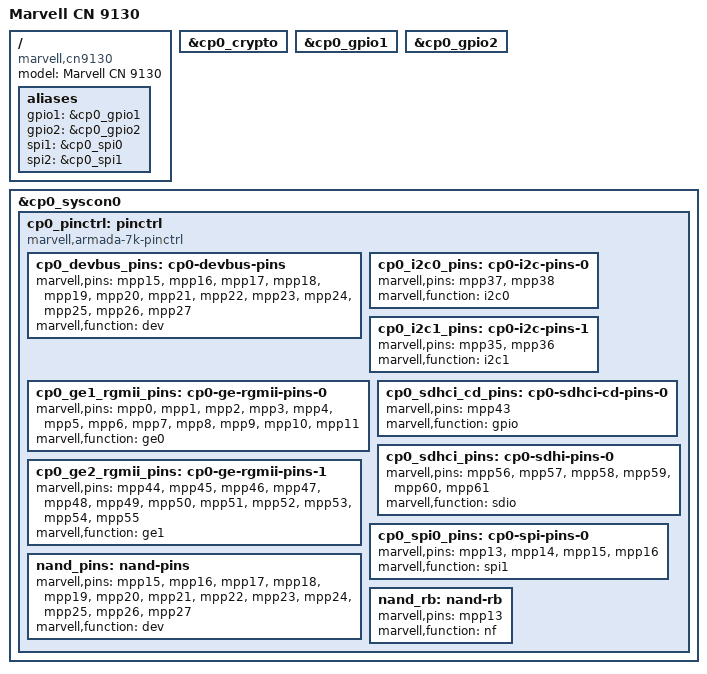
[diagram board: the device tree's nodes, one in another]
/*
 * Copyright (C) 2018 Marvell International Ltd.
 *
 * SPDX-License-Identifier:        GPL-2.0
 * https://spdx.org/licenses
 */

/*
 * Device Tree file for the CN 9130 SoC, made of an AP807 Quad and
 * three CP110.
 */

#include "armada-ap806-quad.dtsi"

/ {
        aliases {
                gpio1 = &cp0_gpio1;
                gpio2 = &cp0_gpio2;
                spi1 = &cp0_spi0;
                spi2 = &cp0_spi1;
        };
};

/* This defines used to calculate the base address of each CP */
#define CP110_PCIE_MEM_SIZE(iface)       ((iface == 0) ? 0x1ff00000 : 0xf00000)
#define CP110_PCIE_BUS_MEM_CFG           (0x82000000)

/* CP110-0 Settings */
#define CP110_NAME                       cp0
#define CP110_NUM                        0
#define CP110_BASE                       f2000000
#define CP110_PCIE0_BASE                 f2600000
#define CP110_PCIE1_BASE                 f2620000
#define CP110_PCIE2_BASE                 f2640000
#define CP110_PCIEx_CPU_MEM_BASE(iface)  ((iface == 0) ? 0xc0000000 : \
                                         (0xe0000000 + (iface - 1) * 0x1000000))
#define CP110_PCIEx_MEM_BASE(iface)      (CP110_PCIEx_CPU_MEM_BASE(iface))

#include "armada-cp110.dtsi"

#undef CP110_NUM
#undef CP110_NAME
#undef CP110_BASE
#undef CP110_PCIE0_BASE
#undef CP110_PCIE1_BASE
#undef CP110_PCIE2_BASE

/ {
        model = "Marvell CN 9130";
        compatible = "marvell,cn9130", "marvell,armada-ap807-quad",
                     "marvell,armada-ap806";
};

&cp0_crypto {
        status = "okay";
};

&cp0_gpio1 {
        status = "okay";
};

&cp0_gpio2 {
        status = "okay";
};

&cp0_syscon0 {
        cp0_pinctrl: pinctrl {
                compatible = "marvell,armada-7k-pinctrl";

                cp0_devbus_pins: cp0-devbus-pins {
                        marvell,pins = "mpp15", "mpp16", "mpp17",
                                       "mpp18", "mpp19", "mpp20",
                                       "mpp21", "mpp22", "mpp23",
                                       "mpp24", "mpp25", "mpp26",
                                       "mpp27";
                        marvell,function = "dev";
                };

                cp0_i2c0_pins: cp0-i2c-pins-0 {
                        marvell,pins = "mpp37", "mpp38";
                        marvell,function = "i2c0";
                };
                cp0_i2c1_pins: cp0-i2c-pins-1 {
                        marvell,pins = "mpp35", "mpp36";
                        marvell,function = "i2c1";
                };
                cp0_ge1_rgmii_pins: cp0-ge-rgmii-pins-0 {
                        marvell,pins = "mpp0", "mpp1", "mpp2",
                                       "mpp3", "mpp4", "mpp5",
                                       "mpp6", "mpp7", "mpp8",
                                       "mpp9", "mpp10", "mpp11";
                        marvell,function = "ge0";
                };
                cp0_ge2_rgmii_pins: cp0-ge-rgmii-pins-1 {
                        marvell,pins = "mpp44", "mpp45", "mpp46",
                                       "mpp47", "mpp48", "mpp49",
                                       "mpp50", "mpp51", "mpp52",
                                       "mpp53", "mpp54", "mpp55";
                        marvell,function = "ge1";
                };
                cp0_sdhci_cd_pins: cp0-sdhci-cd-pins-0 {
                        marvell,pins = "mpp43";
                        marvell,function = "gpio";
                };
                cp0_sdhci_pins: cp0-sdhi-pins-0 {
                        marvell,pins = "mpp56", "mpp57", "mpp58",
                                       "mpp59", "mpp60", "mpp61";
                        marvell,function = "sdio";
                };
                cp0_spi0_pins: cp0-spi-pins-0 {
                        marvell,pins = "mpp13", "mpp14", "mpp15", "mpp16";
                        marvell,function = "spi1";
                };
                nand_pins: nand-pins {
                        marvell,pins =
                        "mpp15", "mpp16", "mpp17", "mpp18", "mpp19",
                        "mpp20", "mpp21", "mpp22", "mpp23", "mpp24",
                        "mpp25", "mpp26", "mpp27";
                        marvell,function = "dev";
                };
                nand_rb: nand-rb {
                        marvell,pins = "mpp13";
                        marvell,function = "nf";
                };
        };
};
